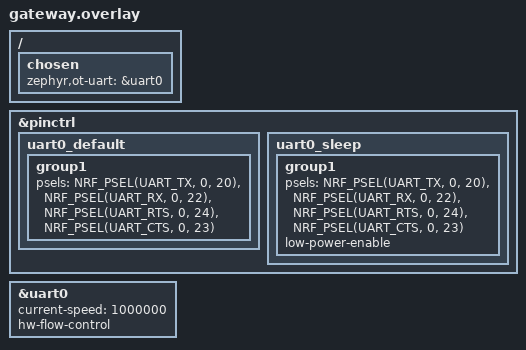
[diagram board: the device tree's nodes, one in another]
&pinctrl {
	uart0_default: uart0_default {
		group1 {
			psels = <NRF_PSEL(UART_TX, 0, 20)>,
			        <NRF_PSEL(UART_RX, 0, 22)>,
			        <NRF_PSEL(UART_RTS, 0, 24)>,
			        <NRF_PSEL(UART_CTS, 0, 23)>;
		};
	};

	uart0_sleep: uart0_sleep {
		group1 {
			psels = <NRF_PSEL(UART_TX, 0, 20)>,
			        <NRF_PSEL(UART_RX, 0, 22)>,
			        <NRF_PSEL(UART_RTS, 0, 24)>,
			        <NRF_PSEL(UART_CTS, 0, 23)>;
			low-power-enable;
		};
	};
};

&uart0 {
	current-speed = <1000000>;
	hw-flow-control;
};

/ {
	chosen {
		zephyr,ot-uart = &uart0;
	};
};
